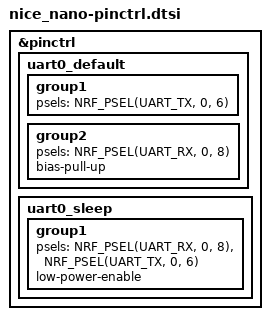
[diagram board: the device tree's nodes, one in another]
&pinctrl {
	/* configuration for uart0 device, default state */
	uart0_default: uart0_default {
		group1 {
			/* configure P0.1 as UART_TX and P0.2 as UART_RTS */
			psels = <NRF_PSEL(UART_TX, 0, 6)>;
		};
		group2 {
			/* configure P0.3 as UART_RX and P0.4 as UART_CTS */
			psels = <NRF_PSEL(UART_RX, 0, 8)>;
			/* both P0.3 and P0.4 are configured with pull-up */
			bias-pull-up;
		};
	};
	
    uart0_sleep: uart0_sleep {
        group1 {
            psels = <NRF_PSEL(UART_RX, 0, 8)>,
                <NRF_PSEL(UART_TX, 0, 6)>;
            low-power-enable;
        };
    };
	
};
